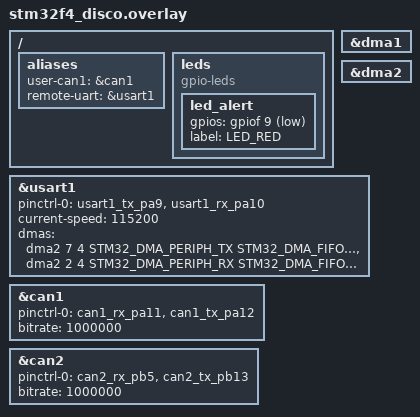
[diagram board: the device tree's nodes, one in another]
#include <dt-bindings/gpio/gpio.h>

/ {
	aliases {
		user-can1 = &can1;
		remote-uart = &usart1;
	};
	leds {
		compatible = "gpio-leds";
		led_alert: led_alert {
			gpios = <&gpiof 9 GPIO_ACTIVE_LOW>;
			label = "LED_RED";
		};
	};
};

&dma1 {
	status = "okay";
};

&dma2 {
	status = "okay";
};

&usart1 {
	pinctrl-0 = <&usart1_tx_pa9 &usart1_rx_pa10>;
	pinctrl-names = "default";
	current-speed = <115200>;
	dmas = <&dma2 7 4 STM32_DMA_PERIPH_TX STM32_DMA_FIFO_FULL>,
	       <&dma2 2 4 STM32_DMA_PERIPH_RX STM32_DMA_FIFO_FULL>;
	dma-names = "tx", "rx";
	status = "okay";
};

/* CAN 总线 — 电机控制 */
&can1 {
	pinctrl-0 = <&can1_rx_pa11 &can1_tx_pa12>;
	pinctrl-names = "default";
	bitrate = <1000000>;
	status = "okay";
};

&can2 {
	pinctrl-0 = <&can2_rx_pb5 &can2_tx_pb13>;
	pinctrl-names = "default";
	bitrate = <1000000>;
	status = "okay";
};
